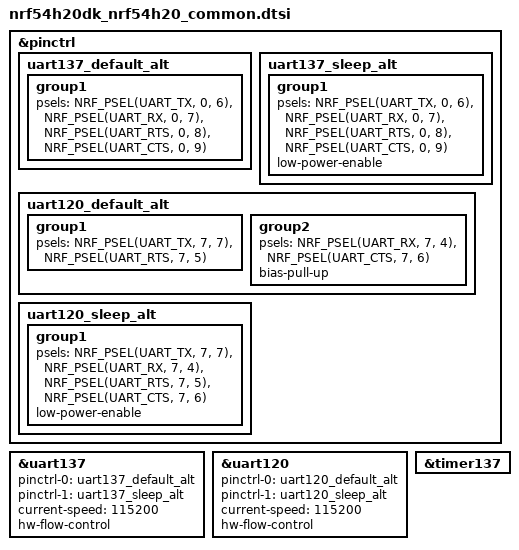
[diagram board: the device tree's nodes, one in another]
/* SPDX-License-Identifier: Apache-2.0 */

&pinctrl {
	uart137_default_alt: uart137_default_alt {
		group1 {
			psels = <NRF_PSEL(UART_TX, 0, 6)>,
				<NRF_PSEL(UART_RX, 0, 7)>,
				<NRF_PSEL(UART_RTS, 0, 8)>,
				<NRF_PSEL(UART_CTS, 0, 9)>;
		};
	};

	uart137_sleep_alt: uart137_sleep_alt {
		group1 {
			psels = <NRF_PSEL(UART_TX, 0, 6)>,
				<NRF_PSEL(UART_RX, 0, 7)>,
				<NRF_PSEL(UART_RTS, 0, 8)>,
				<NRF_PSEL(UART_CTS, 0, 9)>;
			low-power-enable;
		};
	};
	uart120_default_alt: uart120_default_alt {
		group1 {
			psels = <NRF_PSEL(UART_TX, 7, 7)>,
				<NRF_PSEL(UART_RTS, 7, 5)>;
		};
		group2 {
			psels = <NRF_PSEL(UART_RX, 7, 4)>,
				<NRF_PSEL(UART_CTS, 7, 6)>;
			bias-pull-up;
		};
	};

	uart120_sleep_alt: uart120_sleep_alt {
		group1 {
			psels = <NRF_PSEL(UART_TX, 7, 7)>,
				<NRF_PSEL(UART_RX, 7, 4)>,
				<NRF_PSEL(UART_RTS, 7, 5)>,
				<NRF_PSEL(UART_CTS, 7, 6)>;
			low-power-enable;
		};
	};
};

dut: &uart137 {
	status = "okay";
	pinctrl-0 = <&uart137_default_alt>;
	pinctrl-1 = <&uart137_sleep_alt>;
	pinctrl-names = "default", "sleep";
	current-speed = <115200>;
	hw-flow-control;
};

dut2: &uart120 {
	pinctrl-0 = <&uart120_default_alt>;
	pinctrl-1 = <&uart120_sleep_alt>;
	pinctrl-names = "default", "sleep";
	current-speed = <115200>;
	hw-flow-control;
};

counter_dev: &timer137 {
	status = "okay";
};
